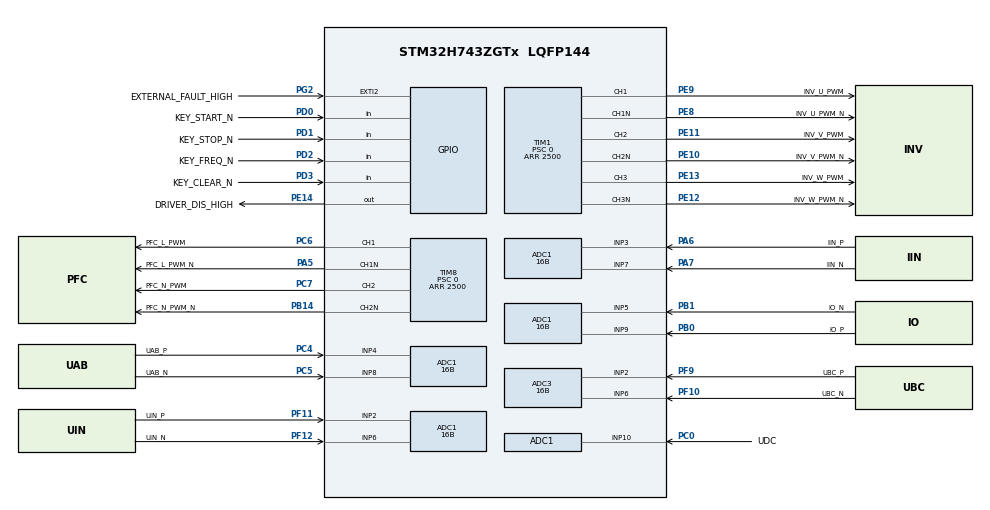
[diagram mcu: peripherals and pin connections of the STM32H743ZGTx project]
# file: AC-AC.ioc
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ADC1.Channel-0\#ChannelRegularConversion=ADC_CHANNEL_2
ADC1.Channel-1\#ChannelRegularConversion=ADC_CHANNEL_6
ADC1.Channel-2\#ChannelRegularConversion=ADC_CHANNEL_3
ADC1.Channel-3\#ChannelRegularConversion=ADC_CHANNEL_7
ADC1.Channel-4\#ChannelRegularConversion=ADC_CHANNEL_4
ADC1.Channel-5\#ChannelRegularConversion=ADC_CHANNEL_8
ADC1.Channel-6\#ChannelRegularConversion=ADC_CHANNEL_9
ADC1.Channel-7\#ChannelRegularConversion=ADC_CHANNEL_5
ADC1.Channel-8\#ChannelRegularConversion=ADC_CHANNEL_10
ADC1.ClockPrescaler=ADC_CLOCK_SYNC_PCLK_DIV4
ADC1.ContinuousConvMode=DISABLE
ADC1.ConversionDataManagement=ADC_CONVERSIONDATA_DMA_CIRCULAR
ADC1.DiscontinuousConvMode=DISABLE
ADC1.EOCSelection=ADC_EOC_SEQ_CONV
ADC1.EnableRegularConversion=ENABLE
ADC1.ExternalTrigConv=ADC_EXTERNALTRIG_T1_TRGO
ADC1.ExternalTrigConvEdge=ADC_EXTERNALTRIGCONVEDGE_RISING
ADC1.LeftBitShift=ADC_LEFTBITSHIFT_NONE
ADC1.LowPowerAutoWait=DISABLE
ADC1.NbrOfConversion=9
ADC1.NbrOfConversionFlag=1
ADC1.OffsetNumber-0\#ChannelRegularConversion=ADC_OFFSET_NONE
ADC1.OffsetNumber-1\#ChannelRegularConversion=ADC_OFFSET_NONE
ADC1.OffsetNumber-2\#ChannelRegularConversion=ADC_OFFSET_NONE
ADC1.OffsetNumber-3\#ChannelRegularConversion=ADC_OFFSET_NONE
ADC1.OffsetNumber-4\#ChannelRegularConversion=ADC_OFFSET_NONE
ADC1.OffsetNumber-5\#ChannelRegularConversion=ADC_OFFSET_NONE
ADC1.OffsetNumber-6\#ChannelRegularConversion=ADC_OFFSET_NONE
ADC1.OffsetNumber-7\#ChannelRegularConversion=ADC_OFFSET_NONE
ADC1.OffsetNumber-8\#ChannelRegularConversion=ADC_OFFSET_NONE
ADC1.OffsetSignedSaturation-0\#ChannelRegularConversion=DISABLE
ADC1.OffsetSignedSaturation-1\#ChannelRegularConversion=DISABLE
ADC1.OffsetSignedSaturation-2\#ChannelRegularConversion=DISABLE
ADC1.OffsetSignedSaturation-3\#ChannelRegularConversion=DISABLE
ADC1.OffsetSignedSaturation-4\#ChannelRegularConversion=DISABLE
ADC1.OffsetSignedSaturation-5\#ChannelRegularConversion=DISABLE
ADC1.OffsetSignedSaturation-6\#ChannelRegularConversion=DISABLE
ADC1.OffsetSignedSaturation-7\#ChannelRegularConversion=DISABLE
ADC1.OffsetSignedSaturation-8\#ChannelRegularConversion=DISABLE
ADC1.Overrun=ADC_OVR_DATA_PRESERVED
ADC1.OversamplingMode=DISABLE
ADC1.Rank-0\#ChannelRegularConversion=1
ADC1.Rank-1\#ChannelRegularConversion=2
ADC1.Rank-2\#ChannelRegularConversion=3
ADC1.Rank-3\#ChannelRegularConversion=4
ADC1.Rank-4\#ChannelRegularConversion=5
ADC1.Rank-5\#ChannelRegularConversion=6
ADC1.Rank-6\#ChannelRegularConversion=7
ADC1.Rank-7\#ChannelRegularConversion=8
ADC1.Rank-8\#ChannelRegularConversion=9
ADC1.Resolution=ADC_RESOLUTION_16B
ADC1.SamplingTime-0\#ChannelRegularConversion=ADC_SAMPLETIME_64CYCLES_5
ADC1.SamplingTime-1\#ChannelRegularConversion=ADC_SAMPLETIME_64CYCLES_5
ADC1.SamplingTime-2\#ChannelRegularConversion=ADC_SAMPLETIME_64CYCLES_5
ADC1.SamplingTime-3\#ChannelRegularConversion=ADC_SAMPLETIME_64CYCLES_5
ADC1.SamplingTime-4\#ChannelRegularConversion=ADC_SAMPLETIME_64CYCLES_5
ADC1.SamplingTime-5\#ChannelRegularConversion=ADC_SAMPLETIME_64CYCLES_5
ADC1.SamplingTime-6\#ChannelRegularConversion=ADC_SAMPLETIME_64CYCLES_5
ADC1.SamplingTime-7\#ChannelRegularConversion=ADC_SAMPLETIME_64CYCLES_5
ADC1.SamplingTime-8\#ChannelRegularConversion=ADC_SAMPLETIME_64CYCLES_5
ADC1.ScanConvMode=ADC_SCAN_ENABLE
ADC1.master=1
ADC3.Channel-0\#ChannelRegularConversion=ADC_CHANNEL_2
ADC3.Channel-1\#ChannelRegularConversion=ADC_CHANNEL_6
ADC3.ClockPrescalerADC3=ADC_CLOCK_SYNC_PCLK_DIV4
ADC3.ContinuousConvMode=DISABLE
ADC3.ConversionDataManagement=ADC_CONVERSIONDATA_DMA_CIRCULAR
ADC3.DiscontinuousConvMode=DISABLE
ADC3.EOCSelection=ADC_EOC_SEQ_CONV
ADC3.EnableRegularConversion=ENABLE
ADC3.ExternalTrigConv=ADC_EXTERNALTRIG_T1_TRGO
ADC3.ExternalTrigConvEdge=ADC_EXTERNALTRIGCONVEDGE_RISING
ADC3.LeftBitShift=ADC_LEFTBITSHIFT_NONE
ADC3.LowPowerAutoWait=DISABLE
ADC3.NbrOfConversion=2
ADC3.NbrOfConversionFlag=1
ADC3.OffsetNumber-0\#ChannelRegularConversion=ADC_OFFSET_NONE
ADC3.OffsetNumber-1\#ChannelRegularConversion=ADC_OFFSET_NONE
ADC3.OffsetSignedSaturation-0\#ChannelRegularConversion=DISABLE
ADC3.OffsetSignedSaturation-1\#ChannelRegularConversion=DISABLE
ADC3.Overrun=ADC_OVR_DATA_PRESERVED
ADC3.OversamplingMode=DISABLE
ADC3.Rank-0\#ChannelRegularConversion=1
ADC3.Rank-1\#ChannelRegularConversion=2
ADC3.Resolution=ADC_RESOLUTION_16B
ADC3.SamplingTime-0\#ChannelRegularConversion=ADC_SAMPLETIME_64CYCLES_5
ADC3.SamplingTime-1\#ChannelRegularConversion=ADC_SAMPLETIME_64CYCLES_5
ADC3.ScanConvMode=ADC_SCAN_ENABLE
CORTEX_M7.CPU_DCache=Disabled
CORTEX_M7.CPU_ICache=Enabled
CORTEX_M7.default_mode_Activation=0
Dma.ADC1.0.Direction=DMA_PERIPH_TO_MEMORY
Dma.ADC1.0.EventEnable=DISABLE
Dma.ADC1.0.FIFOMode=DMA_FIFOMODE_DISABLE
Dma.ADC1.0.Instance=DMA1_Stream0
Dma.ADC1.0.MemDataAlignment=DMA_MDATAALIGN_HALFWORD
Dma.ADC1.0.MemInc=DMA_MINC_ENABLE
Dma.ADC1.0.Mode=DMA_CIRCULAR
Dma.ADC1.0.PeriphDataAlignment=DMA_PDATAALIGN_HALFWORD
Dma.ADC1.0.PeriphInc=DMA_PINC_DISABLE
Dma.ADC1.0.Polarity=HAL_DMAMUX_REQ_GEN_RISING
Dma.ADC1.0.Priority=DMA_PRIORITY_VERY_HIGH
Dma.ADC1.0.RequestNumber=1
Dma.ADC1.0.SignalID=NONE
Dma.ADC1.0.SyncEnable=DISABLE
Dma.ADC1.0.SyncPolarity=HAL_DMAMUX_SYNC_NO_EVENT
Dma.ADC1.0.SyncRequestNumber=1
Dma.ADC1.0.SyncSignalID=NONE
Dma.ADC3.1.Direction=DMA_PERIPH_TO_MEMORY
Dma.ADC3.1.EventEnable=DISABLE
Dma.ADC3.1.FIFOMode=DMA_FIFOMODE_DISABLE
Dma.ADC3.1.Instance=DMA1_Stream1
Dma.ADC3.1.MemDataAlignment=DMA_MDATAALIGN_HALFWORD
Dma.ADC3.1.MemInc=DMA_MINC_ENABLE
Dma.ADC3.1.Mode=DMA_CIRCULAR
Dma.ADC3.1.PeriphDataAlignment=DMA_PDATAALIGN_HALFWORD
Dma.ADC3.1.PeriphInc=DMA_PINC_DISABLE
Dma.ADC3.1.Polarity=HAL_DMAMUX_REQ_GEN_RISING
Dma.ADC3.1.Priority=DMA_PRIORITY_VERY_HIGH
Dma.ADC3.1.RequestNumber=1
Dma.ADC3.1.SignalID=NONE
Dma.ADC3.1.SyncEnable=DISABLE
Dma.ADC3.1.SyncPolarity=HAL_DMAMUX_SYNC_NO_EVENT
Dma.ADC3.1.SyncRequestNumber=1
Dma.ADC3.1.SyncSignalID=NONE
Dma.Request0=ADC1
Dma.Request1=ADC3
Mcu.Family=STM32H7
Mcu.Name=STM32H743ZGTx
Mcu.Package=LQFP144
NVIC.ADC3_IRQn=true\:1\:0\:false\:false\:true\:true\:true\:true
NVIC.ADC_IRQn=true\:1\:0\:false\:false\:true\:true\:true\:true
NVIC.DMA1_Stream0_IRQn=true\:1\:0\:false\:false\:true\:true\:true\:true
NVIC.DMA1_Stream1_IRQn=true\:1\:0\:false\:false\:true\:true\:true\:true
NVIC.EXTI2_IRQn=true\:0\:0\:false\:false\:true\:true\:true\:true
NVIC.PriorityGroup=NVIC_PRIORITYGROUP_4
PA13\ (JTMS/SWDIO).Mode=Serial_Wire
PA13\ (JTMS/SWDIO).Signal=DEBUG_JTMS-SWDIO
PA14\ (JTCK/SWCLK).Mode=Serial_Wire
PA14\ (JTCK/SWCLK).Signal=DEBUG_JTCK-SWCLK
PA5.GPIO_Label=PFC_L_PWM_N
PA5.GPIO_Speed=GPIO_SPEED_FREQ_VERY_HIGH
PA5.Mode=PWM Generation1 CH1 CH1N
PA5.Signal=TIM8_CH1N
PA6.GPIO_Label=IIN_P
PA6.Signal=ADCx_INP3
PA7.GPIO_Label=IIN_N
PA7.Signal=ADCx_INP7
PB0.GPIO_Label=IO_P
PB0.Signal=ADCx_INP9
PB1.GPIO_Label=IO_N
PB1.Signal=ADCx_INP5
PB14.GPIO_Label=PFC_N_PWM_N
PB14.GPIO_Speed=GPIO_SPEED_FREQ_VERY_HIGH
PB14.Mode=PWM Generation2 CH2 CH2N
PB14.Signal=TIM8_CH2N
PC0.GPIO_Label=UDC
PC0.Signal=ADCx_INP10
PC4.GPIO_Label=UAB_P
PC4.Signal=ADCx_INP4
PC5.GPIO_Label=UAB_N
PC5.Signal=ADCx_INP8
PC6.GPIO_Label=PFC_L_PWM
PC6.GPIO_Speed=GPIO_SPEED_FREQ_VERY_HIGH
PC6.Signal=S_TIM8_CH1
PC7.GPIO_Label=PFC_N_PWM
PC7.GPIO_Speed=GPIO_SPEED_FREQ_VERY_HIGH
PC7.Signal=S_TIM8_CH2
PD0.GPIO_Label=KEY_START_N
PD0.GPIO_PuPd=GPIO_PULLUP
PD0.Signal=GPIO_Input
PD1.GPIO_Label=KEY_STOP_N
PD1.GPIO_PuPd=GPIO_PULLUP
PD1.Signal=GPIO_Input
PD2.GPIO_Label=KEY_FREQ_N
PD2.GPIO_PuPd=GPIO_PULLUP
PD2.Signal=GPIO_Input
PD3.GPIO_Label=KEY_CLEAR_N
PD3.GPIO_PuPd=GPIO_PULLUP
PD3.Signal=GPIO_Input
PE10.GPIO_Label=INV_V_PWM_N
PE10.GPIO_Speed=GPIO_SPEED_FREQ_VERY_HIGH
PE10.Mode=PWM Generation2 CH2 CH2N
PE10.Signal=TIM1_CH2N
PE11.GPIO_Label=INV_V_PWM
PE11.GPIO_Speed=GPIO_SPEED_FREQ_VERY_HIGH
PE11.Signal=S_TIM1_CH2
PE12.GPIO_Label=INV_W_PWM_N
PE12.GPIO_Speed=GPIO_SPEED_FREQ_VERY_HIGH
PE12.Mode=PWM Generation3 CH3 CH3N
PE12.Signal=TIM1_CH3N
PE13.GPIO_Label=INV_W_PWM
PE13.GPIO_Speed=GPIO_SPEED_FREQ_VERY_HIGH
PE13.Signal=S_TIM1_CH3
PE14.GPIO_Label=DRIVER_DIS_HIGH
PE14.GPIO_ModeDefaultOutputPP=GPIO_MODE_OUTPUT_PP
PE14.GPIO_PuPd=GPIO_PULLUP
PE14.GPIO_Speed=GPIO_SPEED_FREQ_VERY_HIGH
PE14.PinState=GPIO_PIN_SET
PE14.Signal=GPIO_Output
PE8.GPIO_Label=INV_U_PWM_N
PE8.GPIO_Speed=GPIO_SPEED_FREQ_VERY_HIGH
PE8.Mode=PWM Generation1 CH1 CH1N
PE8.Signal=TIM1_CH1N
PE9.GPIO_Label=INV_U_PWM
PE9.GPIO_Speed=GPIO_SPEED_FREQ_VERY_HIGH
PE9.Signal=S_TIM1_CH1
PF10.GPIO_Label=UBC_N
PF10.Mode=IN6-Single-Ended
PF10.Signal=ADC3_INP6
PF11.GPIO_Label=UIN_P
PF11.Mode=IN2-Single-Ended
PF11.Signal=ADC1_INP2
PF12.GPIO_Label=UIN_N
PF12.Mode=IN6-Single-Ended
PF12.Signal=ADC1_INP6
PF9.GPIO_Label=UBC_P
PF9.Mode=IN2-Single-Ended
PF9.Signal=ADC3_INP2
PG2.GPIO_Label=EXTERNAL_FAULT_HIGH
PG2.GPIO_ModeDefaultEXTI=GPIO_MODE_IT_RISING
PG2.GPIO_PuPd=GPIO_PULLDOWN
PG2.Signal=GPXTI2
PH0-OSC_IN\ (PH0).Mode=HSE-External-Oscillator
PH0-OSC_IN\ (PH0).Signal=RCC_OSC_IN
PH1-OSC_OUT\ (PH1).Mode=HSE-External-Oscillator
PH1-OSC_OUT\ (PH1).Signal=RCC_OSC_OUT
ProjectManager.HeapSize=0x200
ProjectManager.StackSize=0x400
ProjectManager.TargetToolchain=MDK-ARM V5.32
RCC.ADCCLockSelection=RCC_ADCCLKSOURCE_CLKP
RCC.ADCFreq_Value=25000000
RCC.APB1Freq_Value=90000000
RCC.APB2Freq_Value=90000000
RCC.APB3Freq_Value=90000000
RCC.APB4Freq_Value=90000000
RCC.CKPERSourceSelection=RCC_CLKPSOURCE_HSE
RCC.CortexFreq_Value=180000000
RCC.D1CPRE=RCC_SYSCLK_DIV1
RCC.D1PPRE=RCC_APB3_DIV1
RCC.D2PPRE1=RCC_APB1_DIV1
RCC.D2PPRE2=RCC_APB2_DIV1
RCC.D3PPRE=RCC_APB4_DIV1
RCC.DIVM1=5
RCC.DIVM2=5
RCC.DIVN1=72
RCC.DIVN2=40
RCC.DIVP1=2
RCC.DIVP2=4
RCC.DIVQ1=4
RCC.DIVQ2=4
RCC.DIVR1=2
RCC.DIVR2=4
RCC.HCLKFreq_Value=90000000
RCC.HPRE=RCC_HCLK_DIV2
RCC.HSE_VALUE=25000000
RCC.PLL1_VCI_Range=RCC_PLL1VCIRANGE_2
RCC.PLL1_VCO_SEL=RCC_PLL1VCOWIDE
RCC.PLLFRACN=0
RCC.PLLSourceVirtual=RCC_PLLSOURCE_HSE
RCC.PWR_Regulator_Voltage_Scale=PWR_REGULATOR_VOLTAGE_SCALE1
RCC.SYSCLKFreq_VALUE=180000000
RCC.SYSCLKSource=RCC_SYSCLKSOURCE_PLLCLK
RCC.SupplySource=PWR_LDO_SUPPLY
RCC.USBFreq_Value=90000000
SH.ADCx_INP10.0=ADC1_INP10,IN10-Single-Ended
SH.ADCx_INP3.0=ADC1_INP3,IN3-Single-Ended
SH.ADCx_INP4.0=ADC1_INP4,IN4-Single-Ended
SH.ADCx_INP5.0=ADC1_INP5,IN5-Single-Ended
SH.ADCx_INP7.0=ADC1_INP7,IN7-Single-Ended
SH.ADCx_INP8.0=ADC1_INP8,IN8-Single-Ended
SH.ADCx_INP9.0=ADC1_INP9,IN9-Single-Ended
SH.S_TIM1_CH1.0=TIM1_CH1,PWM Generation1 CH1 CH1N
SH.S_TIM1_CH2.0=TIM1_CH2,PWM Generation2 CH2 CH2N
SH.S_TIM1_CH3.0=TIM1_CH3,PWM Generation3 CH3 CH3N
SH.S_TIM8_CH1.0=TIM8_CH1,PWM Generation1 CH1 CH1N
SH.S_TIM8_CH2.0=TIM8_CH2,PWM Generation2 CH2 CH2N
TIM1.AutoReloadPreload=TIM_AUTORELOAD_PRELOAD_ENABLE
TIM1.AutomaticOutput=TIM_AUTOMATICOUTPUT_DISABLE
TIM1.Break2State=TIM_BREAK2_DISABLE
TIM1.BreakState=TIM_BREAK_DISABLE
TIM1.Channel-PWM\ Generation1\ CH1\ CH1N=TIM_CHANNEL_1
TIM1.Channel-PWM\ Generation2\ CH2\ CH2N=TIM_CHANNEL_2
TIM1.Channel-PWM\ Generation3\ CH3\ CH3N=TIM_CHANNEL_3
TIM1.ClockDivision=TIM_CLOCKDIVISION_DIV1
TIM1.CounterMode=TIM_COUNTERMODE_CENTERALIGNED3
TIM1.DeadTime=90
TIM1.OffStateIDLEMode=TIM_OSSI_ENABLE
TIM1.OffStateRunMode=TIM_OSSR_ENABLE
TIM1.Period=2500
TIM1.Prescaler=0
TIM1.Pulse-PWM\ Generation1\ CH1\ CH1N=1250
TIM1.Pulse-PWM\ Generation2\ CH2\ CH2N=1250
TIM1.Pulse-PWM\ Generation3\ CH3\ CH3N=1250
TIM1.RepetitionCounter=1
TIM1.TIM_MasterOutputTrigger=TIM_TRGO_UPDATE
TIM1.TIM_MasterOutputTrigger2=TIM_TRGO2_RESET
TIM1.TIM_MasterSlaveMode=TIM_MASTERSLAVEMODE_ENABLE
TIM8.AutoReloadPreload=TIM_AUTORELOAD_PRELOAD_ENABLE
TIM8.AutomaticOutput=TIM_AUTOMATICOUTPUT_DISABLE
TIM8.Break2State=TIM_BREAK2_DISABLE
TIM8.BreakState=TIM_BREAK_DISABLE
TIM8.Channel-PWM\ Generation1\ CH1\ CH1N=TIM_CHANNEL_1
TIM8.Channel-PWM\ Generation2\ CH2\ CH2N=TIM_CHANNEL_2
TIM8.ClockDivision=TIM_CLOCKDIVISION_DIV1
TIM8.CounterMode=TIM_COUNTERMODE_CENTERALIGNED3
TIM8.DeadTime=90
TIM8.OffStateIDLEMode=TIM_OSSI_ENABLE
TIM8.OffStateRunMode=TIM_OSSR_ENABLE
TIM8.Period=2500
TIM8.Prescaler=0
TIM8.Pulse-PWM\ Generation1\ CH1\ CH1N=1250
TIM8.Pulse-PWM\ Generation2\ CH2\ CH2N=1250
TIM8.RepetitionCounter=1
TIM8.TIM_InputTrigger=TIM_TS_ITR0
TIM8.TIM_MasterOutputTrigger=TIM_TRGO_RESET
TIM8.TIM_MasterOutputTrigger2=TIM_TRGO2_RESET
TIM8.TIM_MasterSlaveMode=TIM_MASTERSLAVEMODE_DISABLE
TIM8.TIM_SlaveMode=TIM_SLAVEMODE_RESET
VP_TIM1_VS_ClockSourceINT.Mode=Internal
VP_TIM8_VS_ClockSourceINT.Mode=Internal
VP_TIM8_VS_ClockSourceITR.Mode=TriggerSource_ITR0
VP_TIM8_VS_ControllerModeReset.Mode=Reset Mode
board=custom

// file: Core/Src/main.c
/* USER CODE BEGIN Header */
/**
  ******************************************************************************
  * @file           : main.c
  * @brief          : Main program body
  ******************************************************************************
  * @attention
  *
  * Copyright (c) 2026 STMicroelectronics.
  * All rights reserved.
  *
  * This software is licensed under terms that can be found in the LICENSE file
  * in the root directory of this software component.
  * If no LICENSE file comes with this software, it is provided AS-IS.
  *
  ******************************************************************************
  */
/* USER CODE END Header */
#include "main.h"
#include "adc.h"
#include "dma.h"
#include "tim.h"
#include "gpio.h"

/* USER CODE BEGIN Includes */
/* 新增：板级控制入口，由 main 初始化和轮询。 */
#include "acac_board.h"

/* USER CODE END Includes */

void SystemClock_Config(void);
void PeriphCommonClock_Config(void);

int main(void)
{

  /* Enable the CPU Cache */

  /* Enable I-Cache---------------------------------------------------------*/
  SCB_EnableICache();

  /* MCU Configuration--------------------------------------------------------*/

  /* Reset of all peripherals, Initializes the Flash interface and the Systick. */
  HAL_Init();

  /* Configure the system clock */
  SystemClock_Config();

  /* Configure the peripherals common clocks */
  PeriphCommonClock_Config();

  /* Initialize all configured peripherals */
  MX_GPIO_Init();
  MX_DMA_Init();
  MX_TIM1_Init();
  MX_TIM8_Init();
  MX_ADC1_Init();
  MX_ADC3_Init();
  /* USER CODE BEGIN 2 */
  /* 新增：CubeMX 初始化完成后，打开 ADC DMA 和触发定时器。 */
  ACAC_Board_Init();

  /* USER CODE END 2 */

  /* Infinite loop */
  while (1)
  {

    /* USER CODE BEGIN 3 */
    /* 新增：处理按键、消抖和采样超时。闭环在 ADC 回调中运行。 */
    ACAC_Board_Poll();
  }
  /* USER CODE END 3 */
}

void SystemClock_Config(void)
{
  RCC_OscInitTypeDef RCC_OscInitStruct = {0};
  RCC_ClkInitTypeDef RCC_ClkInitStruct = {0};

  /** Supply configuration update enable
  */
  HAL_PWREx_ConfigSupply(PWR_LDO_SUPPLY);

  /** Configure the main internal regulator output voltage
  */
  __HAL_PWR_VOLTAGESCALING_CONFIG(PWR_REGULATOR_VOLTAGE_SCALE1);

  while(!__HAL_PWR_GET_FLAG(PWR_FLAG_VOSRDY)) {}

  /** Initializes the RCC Oscillators according to the specified parameters
  * in the RCC_OscInitTypeDef structure.
  */
  RCC_OscInitStruct.OscillatorType = RCC_OSCILLATORTYPE_HSE;
  RCC_OscInitStruct.HSEState = RCC_HSE_ON;
  RCC_OscInitStruct.PLL.PLLState = RCC_PLL_ON;
  RCC_OscInitStruct.PLL.PLLSource = RCC_PLLSOURCE_HSE;
  RCC_OscInitStruct.PLL.PLLM = 5;
  RCC_OscInitStruct.PLL.PLLN = 72;
  RCC_OscInitStruct.PLL.PLLP = 2;
  RCC_OscInitStruct.PLL.PLLQ = 4;
  RCC_OscInitStruct.PLL.PLLR = 2;
  RCC_OscInitStruct.PLL.PLLRGE = RCC_PLL1VCIRANGE_2;
  RCC_OscInitStruct.PLL.PLLVCOSEL = RCC_PLL1VCOWIDE;
  RCC_OscInitStruct.PLL.PLLFRACN = 0;
  if (HAL_RCC_OscConfig(&RCC_OscInitStruct) != HAL_OK)
  {
    Error_Handler();
  }

  /** Initializes the CPU, AHB and APB buses clocks
  */
  RCC_ClkInitStruct.ClockType = RCC_CLOCKTYPE_HCLK|RCC_CLOCKTYPE_SYSCLK
                              |RCC_CLOCKTYPE_PCLK1|RCC_CLOCKTYPE_PCLK2
                              |RCC_CLOCKTYPE_D3PCLK1|RCC_CLOCKTYPE_D1PCLK1;
  RCC_ClkInitStruct.SYSCLKSource = RCC_SYSCLKSOURCE_PLLCLK;
  RCC_ClkInitStruct.SYSCLKDivider = RCC_SYSCLK_DIV1;
  RCC_ClkInitStruct.AHBCLKDivider = RCC_HCLK_DIV2;
  RCC_ClkInitStruct.APB3CLKDivider = RCC_APB3_DIV1;
  RCC_ClkInitStruct.APB1CLKDivider = RCC_APB1_DIV1;
  RCC_ClkInitStruct.APB2CLKDivider = RCC_APB2_DIV1;
  RCC_ClkInitStruct.APB4CLKDivider = RCC_APB4_DIV1;

  /* 新增：沿用已编译验证的示例 Flash 等待周期设置。 */
  // if (HAL_RCC_ClockConfig(&RCC_ClkInitStruct, FLASH_LATENCY_1) != HAL_OK)
  if (HAL_RCC_ClockConfig(&RCC_ClkInitStruct, FLASH_LATENCY_4) != HAL_OK)
  {
    Error_Handler();
  }
}

void PeriphCommonClock_Config(void)
{
  RCC_PeriphCLKInitTypeDef PeriphClkInitStruct = {0};

  /** Initializes the peripherals clock
  */
  PeriphClkInitStruct.PeriphClockSelection = RCC_PERIPHCLK_CKPER;
  PeriphClkInitStruct.CkperClockSelection = RCC_CLKPSOURCE_HSE;
  if (HAL_RCCEx_PeriphCLKConfig(&PeriphClkInitStruct) != HAL_OK)
  {
    Error_Handler();
  }
}

void Error_Handler(void)
{
  /* USER CODE BEGIN Error_Handler_Debug */
  /* User can add his own implementation to report the HAL error return state */
  /* 新增：故障时先禁用驱动和 PWM，再停机。 */
  // __disable_irq();
  // while (1)
  // {
  // }
  ACAC_Board_Fatal();
  /* USER CODE END Error_Handler_Debug */
}
